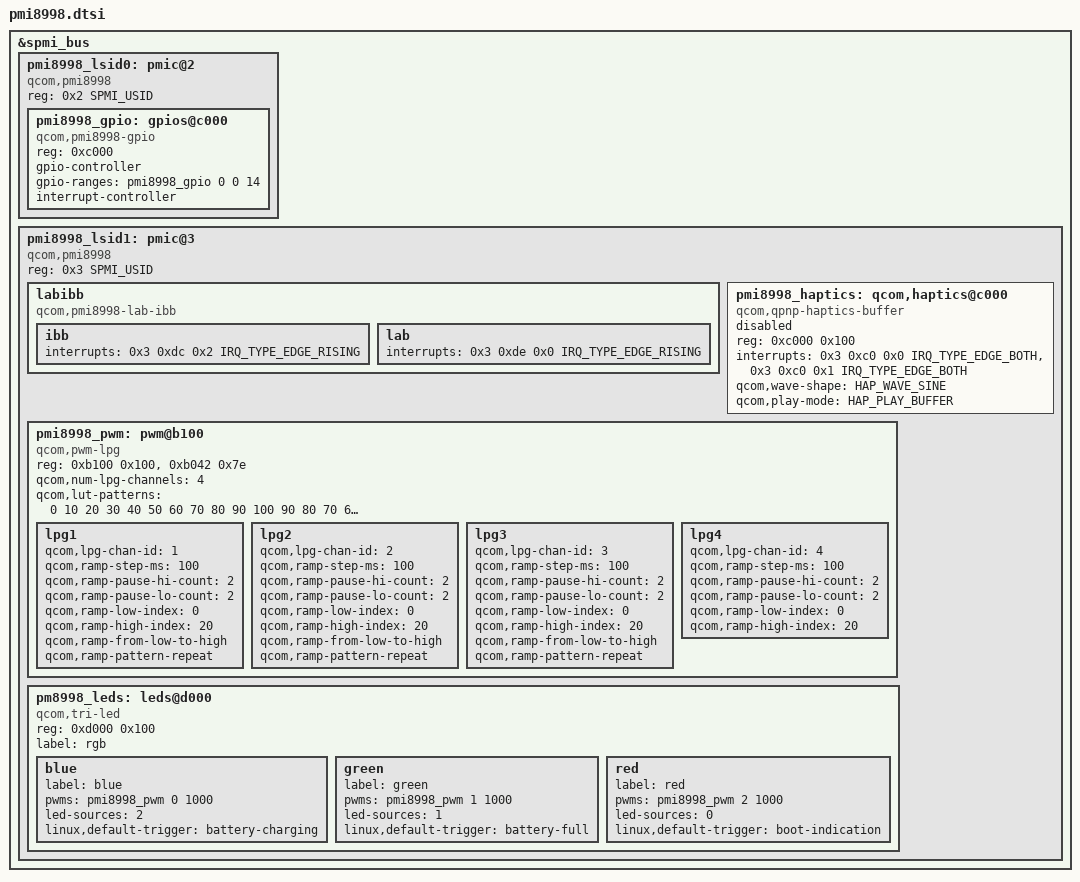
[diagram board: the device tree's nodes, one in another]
// SPDX-License-Identifier: GPL-2.0
#include <dt-bindings/input/qcom,pmi8998-haptics.h>
#include <dt-bindings/interrupt-controller/irq.h>
#include <dt-bindings/spmi/spmi.h>

&spmi_bus {
	pmi8998_lsid0: pmic@2 {
		compatible = "qcom,pmi8998", "qcom,spmi-pmic";
		reg = <0x2 SPMI_USID>;
		#address-cells = <1>;
		#size-cells = <0>;

		pmi8998_gpio: gpios@c000 {
			compatible = "qcom,pmi8998-gpio", "qcom,spmi-gpio";
			reg = <0xc000>;
			gpio-controller;
			gpio-ranges = <&pmi8998_gpio 0 0 14>;
			#gpio-cells = <2>;
			interrupt-controller;
			#interrupt-cells = <2>;
		};
	};

	pmi8998_lsid1: pmic@3 {
		compatible = "qcom,pmi8998", "qcom,spmi-pmic";
		reg = <0x3 SPMI_USID>;
		#address-cells = <1>;
		#size-cells = <0>;

		labibb {
			compatible = "qcom,pmi8998-lab-ibb";

			ibb: ibb {
				interrupts = <0x3 0xdc 0x2 IRQ_TYPE_EDGE_RISING>;
			};

			lab: lab {
				interrupts = <0x3 0xde 0x0 IRQ_TYPE_EDGE_RISING>;
			};
		};

		pmi8998_haptics: qcom,haptics@c000 {
			compatible = "qcom,qpnp-haptics-buffer";
			reg = <0xc000 0x100>;

			interrupts = <0x3 0xc0 0x0 IRQ_TYPE_EDGE_BOTH>,
						 <0x3 0xc0 0x1 IRQ_TYPE_EDGE_BOTH>;
			interrupt-names = "hap-sc-irq", "hap-play-irq";

			qcom,wave-shape = <HAP_WAVE_SINE>;
			qcom,play-mode = <HAP_PLAY_BUFFER>;

			status = "disabled";

			// Unused / unimplemented in code

			// qcom,lra-res-cal-period = <32>;
			// qcom,play-mode = "direct";
			// qcom,actuator-type = <HAP_TYPE_LRA>;
			// qcom,brake-pattern = <0x3 0x3 0x3 0x3>;
		};

		pmi8998_pwm: pwm@b100 {
			compatible = "qcom,pwm-lpg";
			reg = <0xb100 0x100>, <0xb042 0x7e>;
			reg-names = "lpg-base", "lut-base";
			qcom,num-lpg-channels = <4>;
			#pwm-cells = <2>;
			status = "okay";
			qcom,lut-patterns = <0 10 20 30 40 50 60 70 80 90 100
						90 80 70 60 50 40 30 20 10 0>;

			lpg1 {
				qcom,lpg-chan-id = <1>;
				qcom,ramp-step-ms = <100>;
				qcom,ramp-pause-hi-count = <2>;
				qcom,ramp-pause-lo-count = <2>;
				qcom,ramp-low-index = <0>;
				qcom,ramp-high-index = <20>;
				qcom,ramp-from-low-to-high;
				qcom,ramp-pattern-repeat;
			};

			lpg2 {
				qcom,lpg-chan-id = <2>;
				qcom,ramp-step-ms = <100>;
				qcom,ramp-pause-hi-count = <2>;
				qcom,ramp-pause-lo-count = <2>;
				qcom,ramp-low-index = <0>;
				qcom,ramp-high-index = <20>;
				qcom,ramp-from-low-to-high;
				qcom,ramp-pattern-repeat;
			};

			lpg3 {
				qcom,lpg-chan-id = <3>;
				qcom,ramp-step-ms = <100>;
				qcom,ramp-pause-hi-count = <2>;
				qcom,ramp-pause-lo-count = <2>;
				qcom,ramp-low-index = <0>;
				qcom,ramp-high-index = <20>;
				qcom,ramp-from-low-to-high;
				qcom,ramp-pattern-repeat;
			};

			lpg4 {
				qcom,lpg-chan-id = <4>;
				qcom,ramp-step-ms = <100>;
				qcom,ramp-pause-hi-count = <2>;
				qcom,ramp-pause-lo-count = <2>;
				qcom,ramp-low-index = <0>;
				qcom,ramp-high-index = <20>;
			};
                };

		pm8998_leds: leds@d000 {
			compatible = "qcom,tri-led";
			reg = <0xd000 0x100>;
			label = "rgb";

			blue {
				label = "blue";
				pwms = <&pmi8998_pwm 0 1000>;
				led-sources = <2>;
				linux,default-trigger = "battery-charging";
			};

			green {
				label = "green";
				pwms = <&pmi8998_pwm 1 1000>;
				led-sources = <1>;
				linux,default-trigger = "battery-full";
			};

			red {
				label = "red";
				pwms = <&pmi8998_pwm 2 1000>;
				led-sources = <0>;
				linux,default-trigger = "boot-indication";
			};
		};
	};
};
